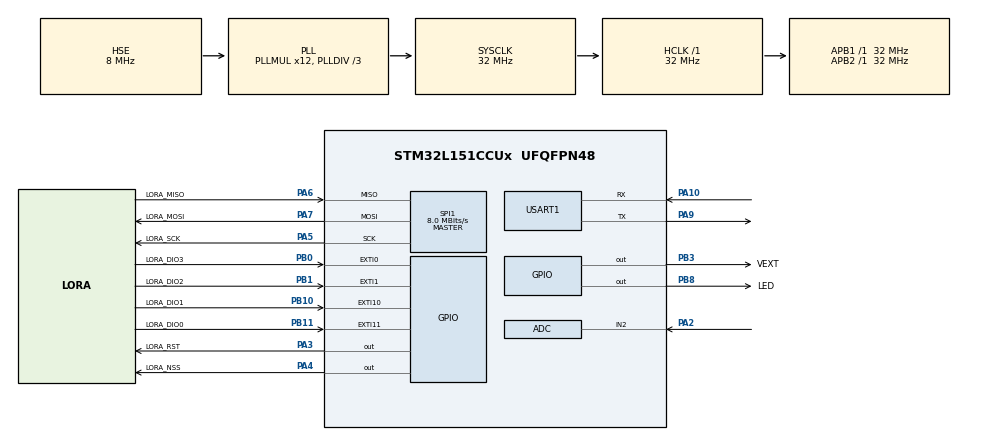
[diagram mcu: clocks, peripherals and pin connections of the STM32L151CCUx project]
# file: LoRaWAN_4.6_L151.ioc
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ADC.Channel-0\#ChannelRegularConversion=ADC_CHANNEL_2
ADC.ClockPrescaler=ADC_CLOCK_ASYNC_DIV2
ADC.EOCSelection=ADC_EOC_SINGLE_CONV
ADC.NbrOfConversionFlag=1
ADC.Rank-0\#ChannelRegularConversion=1
ADC.SamplingTime-0\#ChannelRegularConversion=ADC_SAMPLETIME_4CYCLES
Mcu.Family=STM32L1
Mcu.Name=STM32L151CCUx
Mcu.Package=UFQFPN48
NVIC.EXTI0_IRQn=true\:3\:0\:true\:false\:true\:true\:true\:true
NVIC.EXTI15_10_IRQn=true\:3\:0\:true\:false\:true\:true\:true\:true
NVIC.EXTI1_IRQn=true\:3\:0\:true\:false\:true\:true\:true\:true
NVIC.PriorityGroup=NVIC_PRIORITYGROUP_4
NVIC.RTC_Alarm_IRQn=true\:3\:0\:true\:false\:true\:true\:true\:true
PA10.Mode=Asynchronous
PA10.Signal=USART1_RX
PA13.Mode=Serial_Wire
PA13.Signal=SYS_JTMS-SWDIO
PA14.Mode=Serial_Wire
PA14.Signal=SYS_JTCK-SWCLK
PA2.Mode=IN2
PA2.Signal=ADC_IN2
PA3.GPIO_Label=LORA_RST
PA3.Signal=GPIO_Output
PA4.GPIO_Label=LORA_NSS
PA4.Signal=GPIO_Output
PA5.GPIO_Label=LORA_SCK
PA5.Mode=Full_Duplex_Master
PA5.Signal=SPI1_SCK
PA6.GPIO_Label=LORA_MISO
PA6.Mode=Full_Duplex_Master
PA6.Signal=SPI1_MISO
PA7.GPIO_Label=LORA_MOSI
PA7.Mode=Full_Duplex_Master
PA7.Signal=SPI1_MOSI
PA9.Mode=Asynchronous
PA9.Signal=USART1_TX
PB0.GPIO_Label=LORA_DIO3
PB0.Signal=GPXTI0
PB1.GPIO_Label=LORA_DIO2
PB1.Signal=GPXTI1
PB10.GPIO_Label=LORA_DIO1
PB10.Signal=GPXTI10
PB11.GPIO_Label=LORA_DIO0
PB11.Signal=GPXTI11
PB3.GPIO_Label=VEXT
PB3.Signal=GPIO_Output
PB8.GPIO_Label=LED
PB8.Signal=GPIO_Output
PC14-OSC32_IN.Mode=LSE-External-Oscillator
PC14-OSC32_IN.Signal=RCC_OSC32_IN
PC15-OSC32_OUT.Mode=LSE-External-Oscillator
PC15-OSC32_OUT.Signal=RCC_OSC32_OUT
PH0-OSC_IN.Mode=HSE-External-Oscillator
PH0-OSC_IN.Signal=RCC_OSC_IN
PH1-OSC_OUT.Mode=HSE-External-Oscillator
PH1-OSC_OUT.Signal=RCC_OSC_OUT
ProjectManager.HeapSize=0x1000
ProjectManager.StackSize=0x1000
ProjectManager.TargetToolchain=MDK-ARM V5.32
RCC.48MHZClocksFreq_Value=48000000
RCC.AHBFreq_Value=32000000
RCC.APB1Freq_Value=32000000
RCC.APB1TimFreq_Value=32000000
RCC.APB2Freq_Value=32000000
RCC.APB2TimFreq_Value=32000000
RCC.EnableCSSLSE=true
RCC.HCLKFreq_Value=32000000
RCC.HSE_VALUE=8000000
RCC.HSI_VALUE=16000000
RCC.MSI_VALUE=2097000
RCC.PLLDIV=RCC_PLL_DIV3
RCC.PLLMUL=RCC_PLL_MUL12
RCC.PLLSourceVirtual=RCC_PLLSOURCE_HSE
RCC.RTCClockSelection=RCC_RTCCLKSOURCE_LSE
RCC.RTCClockSelectionVirtual=RCC_RTCCLKSOURCE_LSE
RCC.SYSCLKFreq_VALUE=32000000
RCC.SYSCLKSource=RCC_SYSCLKSOURCE_PLLCLK
RCC.VCOOutputFreq_Value=96000000
RTC.Alarm-Alarm\ A=RTC_ALARM_A
RTC.AsynchPrediv=31
RTC.SynchPrediv=1023
SPI1.BaudRatePrescaler=SPI_BAUDRATEPRESCALER_4
SPI1.CalculateBaudRate=8.0 MBits/s
SPI1.Direction=SPI_DIRECTION_2LINES
SPI1.Mode=SPI_MODE_MASTER
SPI1.VirtualType=VM_MASTER
USART1.VirtualMode=VM_ASYNC
VP_RTC_VS_RTC_Activate.Mode=RTC_Enabled
VP_RTC_VS_RTC_Alarm_A_Intern.Mode=Alarm A
VP_RTC_VS_RTC_Calendar.Mode=RTC_Calendar
board=custom

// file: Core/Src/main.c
/* USER CODE BEGIN Header */
/**
  ******************************************************************************
  * @file           : main.c
  * @brief          : Main program body
  ******************************************************************************
  * @attention
  *
  * Copyright (c) 2022 STMicroelectronics.
  * All rights reserved.
  *
  * This software is licensed under terms that can be found in the LICENSE file
  * in the root directory of this software component.
  * If no LICENSE file comes with this software, it is provided AS-IS.
  *
  ******************************************************************************
  */
/* USER CODE END Header */
#include "main.h"
#include "adc.h"
#include "rtc.h"
#include "spi.h"
#include "usart.h"
#include "gpio.h"

/* USER CODE BEGIN Includes */
#include "lorawan_app.h"

/* USER CODE END Includes */

void SystemClock_Config(void);

int main(void)
{

  /* MCU Configuration--------------------------------------------------------*/

  /* Reset of all peripherals, Initializes the Flash interface and the Systick. */
  HAL_Init();

  /* Configure the system clock */
  SystemClock_Config();

  /* Initialize all configured peripherals */
  MX_GPIO_Init();
  MX_RTC_Init();
  MX_USART1_UART_Init();
  MX_ADC_Init();
  MX_SPI1_Init();

  /* Infinite loop */
  while (1)
  {

    /* USER CODE BEGIN 3 */
	  	  usb_printf("hello world%d\r\n",IOE_1);

	  	  lorawan_app();

  }
  /* USER CODE END 3 */
}

void SystemClock_Config(void)
{
  RCC_OscInitTypeDef RCC_OscInitStruct = {0};
  RCC_ClkInitTypeDef RCC_ClkInitStruct = {0};
  RCC_PeriphCLKInitTypeDef PeriphClkInit = {0};

  /** Configure the main internal regulator output voltage
  */
  __HAL_PWR_VOLTAGESCALING_CONFIG(PWR_REGULATOR_VOLTAGE_SCALE1);

  /** Initializes the RCC Oscillators according to the specified parameters
  * in the RCC_OscInitTypeDef structure.
  */
  RCC_OscInitStruct.OscillatorType = RCC_OSCILLATORTYPE_HSI|RCC_OSCILLATORTYPE_HSE
                              |RCC_OSCILLATORTYPE_LSE;
  RCC_OscInitStruct.HSEState = RCC_HSE_ON;
  RCC_OscInitStruct.LSEState = RCC_LSE_ON;
  RCC_OscInitStruct.HSIState = RCC_HSI_ON;
  RCC_OscInitStruct.HSICalibrationValue = RCC_HSICALIBRATION_DEFAULT;
  RCC_OscInitStruct.PLL.PLLState = RCC_PLL_ON;
  RCC_OscInitStruct.PLL.PLLSource = RCC_PLLSOURCE_HSE;
  RCC_OscInitStruct.PLL.PLLMUL = RCC_PLL_MUL12;
  RCC_OscInitStruct.PLL.PLLDIV = RCC_PLL_DIV3;
  if (HAL_RCC_OscConfig(&RCC_OscInitStruct) != HAL_OK)
  {
    Error_Handler();
  }

  /** Initializes the CPU, AHB and APB buses clocks
  */
  RCC_ClkInitStruct.ClockType = RCC_CLOCKTYPE_HCLK|RCC_CLOCKTYPE_SYSCLK
                              |RCC_CLOCKTYPE_PCLK1|RCC_CLOCKTYPE_PCLK2;
  RCC_ClkInitStruct.SYSCLKSource = RCC_SYSCLKSOURCE_PLLCLK;
  RCC_ClkInitStruct.AHBCLKDivider = RCC_SYSCLK_DIV1;
  RCC_ClkInitStruct.APB1CLKDivider = RCC_HCLK_DIV1;
  RCC_ClkInitStruct.APB2CLKDivider = RCC_HCLK_DIV1;

  if (HAL_RCC_ClockConfig(&RCC_ClkInitStruct, FLASH_LATENCY_1) != HAL_OK)
  {
    Error_Handler();
  }
  PeriphClkInit.PeriphClockSelection = RCC_PERIPHCLK_RTC;
  PeriphClkInit.RTCClockSelection = RCC_RTCCLKSOURCE_LSE;
  if (HAL_RCCEx_PeriphCLKConfig(&PeriphClkInit) != HAL_OK)
  {
    Error_Handler();
  }

  /** Enables the Clock Security System
  */
  HAL_RCCEx_EnableLSECSS();
}

void Error_Handler(void)
{
  __disable_irq();
  while (1)
  {
  }
}

//#ifdef  USE_FULL_ASSERT
///**
//  * @brief  Reports the name of the source file and the source line number
//  *         where the assert_param error has occurred.
//  * @param  file: pointer to the source file name
//  * @param  line: assert_param error line source number
//  * @retval None
//  */
//void assert_failed(uint8_t *file, uint32_t line)
//{
//  /* USER CODE BEGIN 6 */
//  /* User can add his own implementation to report the file name and line number,
//     ex: printf("Wrong parameters value: file %s on line %d\r\n", file, line) */
//  /* USER CODE END 6 */
//}
//#endif /* USE_FULL_ASSERT */
